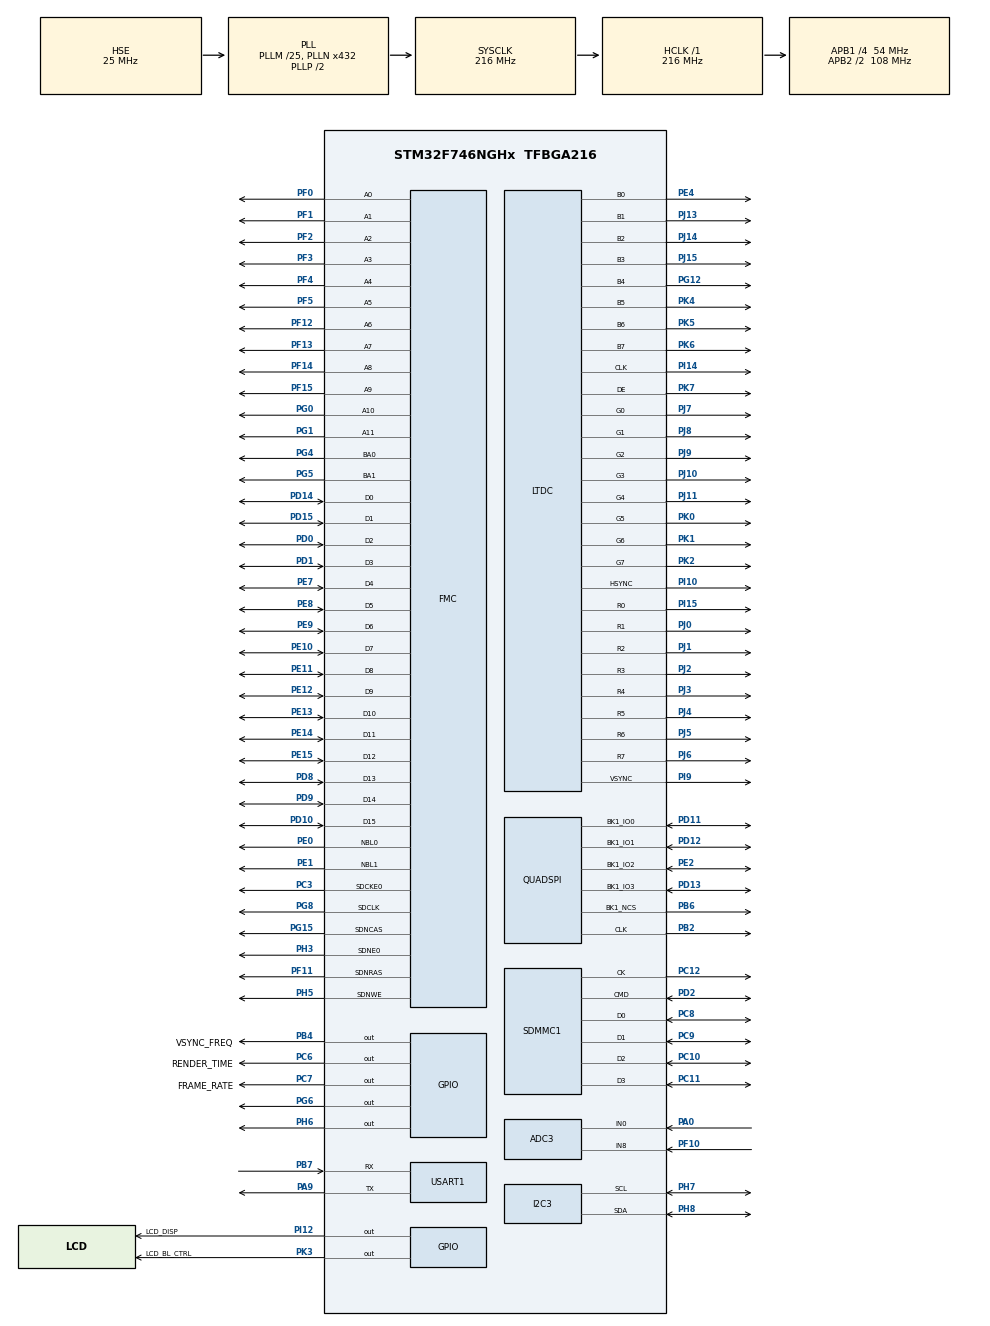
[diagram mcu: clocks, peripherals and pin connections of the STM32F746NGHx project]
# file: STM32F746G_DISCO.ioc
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ADC3.Channel-0\#ChannelRegularConversion=ADC_CHANNEL_0
ADC3.Channel-1\#ChannelRegularConversion=ADC_CHANNEL_8
ADC3.ContinuousConvMode=ENABLE
ADC3.DMAContinuousRequests=ENABLE
ADC3.NbrOfConversion=2
ADC3.NbrOfConversionFlag=1
ADC3.Rank-0\#ChannelRegularConversion=1
ADC3.Rank-1\#ChannelRegularConversion=2
ADC3.SamplingTime-0\#ChannelRegularConversion=ADC_SAMPLETIME_480CYCLES
ADC3.SamplingTime-1\#ChannelRegularConversion=ADC_SAMPLETIME_480CYCLES
ADC3.ScanConvMode=ADC_SCAN_ENABLE
CORTEX_M7.ART_ACCLERATOR_ENABLE=1
CORTEX_M7.AccessPermission-Cortex_Memory_Protection_Unit_Region0_Settings=MPU_REGION_FULL_ACCESS
CORTEX_M7.AccessPermission-Cortex_Memory_Protection_Unit_Region1_Settings=MPU_REGION_FULL_ACCESS
CORTEX_M7.BaseAddress-Cortex_Memory_Protection_Unit_Region0_Settings=0x90000000
CORTEX_M7.BaseAddress-Cortex_Memory_Protection_Unit_Region1_Settings=0x90000000
CORTEX_M7.CPU_DCache=Enabled
CORTEX_M7.CPU_ICache=Enabled
CORTEX_M7.Enable-Cortex_Memory_Protection_Unit_Region0_Settings=MPU_REGION_ENABLE
CORTEX_M7.Enable-Cortex_Memory_Protection_Unit_Region1_Settings=MPU_REGION_ENABLE
CORTEX_M7.IsCacheable-Cortex_Memory_Protection_Unit_Region1_Settings=MPU_ACCESS_CACHEABLE
CORTEX_M7.MPU_Control=MPU_PRIVILEGED_DEFAULT
CORTEX_M7.PREFETCH_ENABLE=1
CORTEX_M7.Size-Cortex_Memory_Protection_Unit_Region0_Settings=MPU_REGION_SIZE_256MB
CORTEX_M7.Size-Cortex_Memory_Protection_Unit_Region1_Settings=MPU_REGION_SIZE_16MB
Dma.ADC3.2.Direction=DMA_PERIPH_TO_MEMORY
Dma.ADC3.2.FIFOMode=DMA_FIFOMODE_DISABLE
Dma.ADC3.2.Instance=DMA2_Stream0
Dma.ADC3.2.MemDataAlignment=DMA_MDATAALIGN_HALFWORD
Dma.ADC3.2.MemInc=DMA_MINC_ENABLE
Dma.ADC3.2.Mode=DMA_CIRCULAR
Dma.ADC3.2.PeriphDataAlignment=DMA_PDATAALIGN_HALFWORD
Dma.ADC3.2.PeriphInc=DMA_PINC_DISABLE
Dma.ADC3.2.Priority=DMA_PRIORITY_LOW
Dma.Request0=SDMMC1_RX
Dma.Request1=SDMMC1_TX
Dma.Request2=ADC3
Dma.SDMMC1_RX.0.Direction=DMA_PERIPH_TO_MEMORY
Dma.SDMMC1_RX.0.FIFOMode=DMA_FIFOMODE_ENABLE
Dma.SDMMC1_RX.0.FIFOThreshold=DMA_FIFO_THRESHOLD_FULL
Dma.SDMMC1_RX.0.Instance=DMA2_Stream3
Dma.SDMMC1_RX.0.MemBurst=DMA_MBURST_INC4
Dma.SDMMC1_RX.0.MemDataAlignment=DMA_MDATAALIGN_WORD
Dma.SDMMC1_RX.0.MemInc=DMA_MINC_ENABLE
Dma.SDMMC1_RX.0.Mode=DMA_PFCTRL
Dma.SDMMC1_RX.0.PeriphBurst=DMA_PBURST_INC4
Dma.SDMMC1_RX.0.PeriphDataAlignment=DMA_PDATAALIGN_WORD
Dma.SDMMC1_RX.0.PeriphInc=DMA_PINC_DISABLE
Dma.SDMMC1_RX.0.Priority=DMA_PRIORITY_LOW
Dma.SDMMC1_TX.1.Direction=DMA_MEMORY_TO_PERIPH
Dma.SDMMC1_TX.1.FIFOMode=DMA_FIFOMODE_ENABLE
Dma.SDMMC1_TX.1.FIFOThreshold=DMA_FIFO_THRESHOLD_FULL
Dma.SDMMC1_TX.1.Instance=DMA2_Stream6
Dma.SDMMC1_TX.1.MemBurst=DMA_MBURST_INC4
Dma.SDMMC1_TX.1.MemDataAlignment=DMA_MDATAALIGN_WORD
Dma.SDMMC1_TX.1.MemInc=DMA_MINC_ENABLE
Dma.SDMMC1_TX.1.Mode=DMA_PFCTRL
Dma.SDMMC1_TX.1.PeriphBurst=DMA_PBURST_INC4
Dma.SDMMC1_TX.1.PeriphDataAlignment=DMA_PDATAALIGN_WORD
Dma.SDMMC1_TX.1.PeriphInc=DMA_PINC_DISABLE
Dma.SDMMC1_TX.1.Priority=DMA_PRIORITY_LOW
FATFS._MAX_SS=4096
FMC.CASLatency1=FMC_SDRAM_CAS_LATENCY_3
FMC.ExitSelfRefreshDelay1=7
FMC.LoadToActiveDelay1=2
FMC.RCDDelay1=2
FMC.RPDelay1=2
FMC.ReadBurst1=FMC_SDRAM_RBURST_ENABLE
FMC.RowCycleDelay1=7
FMC.SDClockPeriod1=FMC_SDRAM_CLOCK_PERIOD_2
FMC.SelfRefreshTime1=4
FMC.WriteRecoveryTime1=3
FREERTOS.Queues01=adcCurrentQueue,10,uint16_t,0,Dynamic,NULL,NULL;adcVoltageQueue,10,uint16_t,0,Dynamic,NULL,NULL;sdQueue,16,uint16_t,0,Dynamic,NULL,NULL
FREERTOS.Tasks01=defaultTask,24,128,StartDefaultTask,Default,NULL,Dynamic,NULL,NULL;TouchGFXTask,24,4096,TouchGFX_Task,As external,NULL,Dynamic,NULL,NULL;videoTask,8,1000,videoTaskFunc,As external,NULL,Dynamic,NULL,NULL;adcCurrentTask,8,128,StartAdcCurrentTask,Default,NULL,Dynamic,NULL,NULL;adcVoltageTask,8,128,StartAdcVoltageTask,Default,NULL,Dynamic,NULL,NULL;sdTask,8,128,StartSDTask,Default,NULL,Dynamic,NULL,NULL
FREERTOS.configTOTAL_HEAP_SIZE=75000
FREERTOS.configUSE_APPLICATION_TASK_TAG=1
FREERTOS.configUSE_IDLE_HOOK=1
I2C3.Timing=0x20404768
LIBJPEG.RGB_ORDERING=BGR
LTDC.ActiveH=272
LTDC.ActiveW=480
LTDC.Alpha_L0=255
LTDC.FBStartAdress_L0=0xC0000000
LTDC.HBP=13
LTDC.HFP=32
LTDC.HSync=41
LTDC.ImageHeight_L0=272
LTDC.ImageWidth_L0=480
LTDC.Layers=0
LTDC.PixelFormat_L0=LTDC_PIXEL_FORMAT_RGB565
LTDC.VSync=10
LTDC.WindowX1_L0=480
LTDC.WindowY1_L0=272
Mcu.Family=STM32F7
Mcu.Name=STM32F746NGHx
Mcu.Package=TFBGA216
NVIC.DMA2D_IRQn=true\:5\:0\:true\:false\:true\:true\:true\:true\:true
NVIC.DMA2_Stream0_IRQn=true\:5\:0\:false\:false\:true\:true\:false\:true\:true
NVIC.DMA2_Stream3_IRQn=true\:5\:0\:false\:false\:true\:true\:false\:true\:true
NVIC.DMA2_Stream6_IRQn=true\:5\:0\:false\:false\:true\:true\:false\:true\:true
NVIC.LTDC_IRQn=true\:5\:0\:true\:false\:true\:true\:true\:true\:true
NVIC.PriorityGroup=NVIC_PRIORITYGROUP_4
NVIC.SDMMC1_IRQn=true\:5\:0\:false\:false\:true\:true\:true\:true\:true
NVIC.TIM6_DAC_IRQn=true\:0\:0\:false\:false\:true\:false\:false\:true\:true
NVIC.TimeBase=TIM6_DAC_IRQn
NVIC.TimeBaseIP=TIM6
PA0/WKUP.Signal=ADCx_IN0
PA13.Mode=Serial_Wire
PA13.Signal=SYS_JTMS-SWDIO
PA14.Mode=Serial_Wire
PA14.Signal=SYS_JTCK-SWCLK
PA9.Mode=Asynchronous
PA9.Signal=USART1_TX
PB2.Mode=Single Bank 1
PB2.Signal=QUADSPI_CLK
PB4.GPIO_Label=VSYNC_FREQ
PB4.GPIO_Speed=GPIO_SPEED_FREQ_VERY_HIGH
PB4.Signal=GPIO_Output
PB6.Mode=Single Bank 1
PB6.Signal=QUADSPI_BK1_NCS
PB7.Mode=Asynchronous
PB7.Signal=USART1_RX
PC10.Mode=SD_4_bits_Wide_bus
PC10.Signal=SDMMC1_D2
PC11.Mode=SD_4_bits_Wide_bus
PC11.Signal=SDMMC1_D3
PC12.Mode=SD_4_bits_Wide_bus
PC12.Signal=SDMMC1_CK
PC14/OSC32_IN.Mode=LSE-External-Oscillator
PC14/OSC32_IN.Signal=RCC_OSC32_IN
PC15/OSC32_OUT.Mode=LSE-External-Oscillator
PC15/OSC32_OUT.Signal=RCC_OSC32_OUT
PC3.Mode=SdramChipSelect1_1
PC3.Signal=FMC_SDCKE0
PC6.GPIO_Label=RENDER_TIME
PC6.GPIO_Speed=GPIO_SPEED_FREQ_VERY_HIGH
PC6.Signal=GPIO_Output
PC7.GPIO_Label=FRAME_RATE
PC7.GPIO_Speed=GPIO_SPEED_FREQ_VERY_HIGH
PC7.Signal=GPIO_Output
PC8.Mode=SD_4_bits_Wide_bus
PC8.Signal=SDMMC1_D0
PC9.Mode=SD_4_bits_Wide_bus
PC9.Signal=SDMMC1_D1
PD0.Signal=FMC_D2_DA2
PD1.Signal=FMC_D3_DA3
PD10.Signal=FMC_D15_DA15
PD11.Mode=Single Bank 1
PD11.Signal=QUADSPI_BK1_IO0
PD12.Mode=Single Bank 1
PD12.Signal=QUADSPI_BK1_IO1
PD13.Mode=Single Bank 1
PD13.Signal=QUADSPI_BK1_IO3
PD14.Signal=FMC_D0_DA0
PD15.Signal=FMC_D1_DA1
PD2.Mode=SD_4_bits_Wide_bus
PD2.Signal=SDMMC1_CMD
PD8.Signal=FMC_D13_DA13
PD9.Signal=FMC_D14_DA14
PE0.Signal=FMC_NBL0
PE1.Signal=FMC_NBL1
PE10.Signal=FMC_D7_DA7
PE11.Signal=FMC_D8_DA8
PE12.Signal=FMC_D9_DA9
PE13.Signal=FMC_D10_DA10
PE14.Signal=FMC_D11_DA11
PE15.Signal=FMC_D12_DA12
PE2.Mode=Single Bank 1
PE2.Signal=QUADSPI_BK1_IO2
PE4.Mode=RGB888
PE4.Signal=LTDC_B0
PE7.Signal=FMC_D4_DA4
PE8.Signal=FMC_D5_DA5
PE9.Signal=FMC_D6_DA6
PF0.Signal=FMC_A0
PF1.Signal=FMC_A1
PF10.Mode=IN8
PF10.Signal=ADC3_IN8
PF11.Signal=FMC_SDNRAS
PF12.Signal=FMC_A6
PF13.Signal=FMC_A7
PF14.Signal=FMC_A8
PF15.Signal=FMC_A9
PF2.Signal=FMC_A2
PF3.Signal=FMC_A3
PF4.Signal=FMC_A4
PF5.Signal=FMC_A5
PG0.Signal=FMC_A10
PG1.Signal=FMC_A11
PG12.Mode=RGB888
PG12.Signal=LTDC_B4
PG15.Signal=FMC_SDNCAS
PG4.Signal=FMC_A14_BA0
PG5.Signal=FMC_A15_BA1
PG6.GPIO_PuPd=GPIO_PULLDOWN
PG6.PinState=GPIO_PIN_SET
PG6.Signal=GPIO_Output
PG8.Signal=FMC_SDCLK
PH0/OSC_IN.Mode=HSE-External-Oscillator
PH0/OSC_IN.Signal=RCC_OSC_IN
PH1/OSC_OUT.Mode=HSE-External-Oscillator
PH1/OSC_OUT.Signal=RCC_OSC_OUT
PH3.Mode=SdramChipSelect1_1
PH3.Signal=FMC_SDNE0
PH5.Signal=FMC_SDNWE
PH6.GPIO_PuPd=GPIO_PULLDOWN
PH6.PinState=GPIO_PIN_SET
PH6.Signal=GPIO_Output
PH7.GPIO_Pu=GPIO_PULLUP
PH7.Mode=I2C
PH7.Signal=I2C3_SCL
PH8.GPIO_Pu=GPIO_PULLUP
PH8.Mode=I2C
PH8.Signal=I2C3_SDA
PI10.Mode=RGB888
PI10.Signal=LTDC_HSYNC
PI12.GPIO_Label=LCD_DISP
PI12.PinState=GPIO_PIN_SET
PI12.Signal=GPIO_Output
PI14.Mode=RGB888
PI14.Signal=LTDC_CLK
PI15.Mode=RGB888
PI15.Signal=LTDC_R0
PI9.Mode=RGB888
PI9.Signal=LTDC_VSYNC
PJ0.Mode=RGB888
PJ0.Signal=LTDC_R1
PJ1.Mode=RGB888
PJ1.Signal=LTDC_R2
PJ10.Mode=RGB888
PJ10.Signal=LTDC_G3
PJ11.Mode=RGB888
PJ11.Signal=LTDC_G4
PJ13.Mode=RGB888
PJ13.Signal=LTDC_B1
PJ14.Mode=RGB888
PJ14.Signal=LTDC_B2
PJ15.Mode=RGB888
PJ15.Signal=LTDC_B3
PJ2.Mode=RGB888
PJ2.Signal=LTDC_R3
PJ3.Mode=RGB888
PJ3.Signal=LTDC_R4
PJ4.Mode=RGB888
PJ4.Signal=LTDC_R5
PJ5.Mode=RGB888
PJ5.Signal=LTDC_R6
PJ6.Mode=RGB888
PJ6.Signal=LTDC_R7
PJ7.Mode=RGB888
PJ7.Signal=LTDC_G0
PJ8.Mode=RGB888
PJ8.Signal=LTDC_G1
PJ9.Mode=RGB888
PJ9.Signal=LTDC_G2
PK0.Mode=RGB888
PK0.Signal=LTDC_G5
PK1.Mode=RGB888
PK1.Signal=LTDC_G6
PK2.Mode=RGB888
PK2.Signal=LTDC_G7
PK3.GPIO_Label=LCD_BL_CTRL
PK3.PinState=GPIO_PIN_SET
PK3.Signal=GPIO_Output
PK4.Mode=RGB888
PK4.Signal=LTDC_B5
PK5.Mode=RGB888
PK5.Signal=LTDC_B6
PK6.Mode=RGB888
PK6.Signal=LTDC_B7
PK7.Mode=RGB888
PK7.Signal=LTDC_DE
ProjectManager.HeapSize=0xA00
ProjectManager.StackSize=0xA00
ProjectManager.TargetToolchain=STM32CubeIDE
QUADSPI.ChipSelectHighTime=QSPI_CS_HIGH_TIME_6_CYCLE
QUADSPI.ClockPrescaler=1
QUADSPI.FifoThreshold=4
QUADSPI.FlashSize=24
QUADSPI.SampleShifting=QSPI_SAMPLE_SHIFTING_HALFCYCLE
RCC.AHBFreq_Value=216000000
RCC.APB1CLKDivider=RCC_HCLK_DIV4
RCC.APB1Freq_Value=54000000
RCC.APB1TimFreq_Value=108000000
RCC.APB2CLKDivider=RCC_HCLK_DIV2
RCC.APB2Freq_Value=108000000
RCC.APB2TimFreq_Value=216000000
RCC.CortexFreq_Value=216000000
RCC.HCLKFreq_Value=216000000
RCC.HSE_VALUE=25000000
RCC.HSI_VALUE=16000000
RCC.PLLI2SN=100
RCC.PLLM=25
RCC.PLLN=432
RCC.PLLQ=9
RCC.PLLSAIR=3
RCC.PLLSourceVirtual=RCC_PLLSOURCE_HSE
RCC.RTCClockSelection=RCC_RTCCLKSOURCE_LSE
RCC.SDMMCClockSelection=RCC_SDMMC1CLKSOURCE_CLK48
RCC.SYSCLKFreq_VALUE=216000000
RCC.SYSCLKSource=RCC_SYSCLKSOURCE_PLLCLK
RCC.USBFreq_Value=48000000
RCC.VCOOutputFreq_Value=432000000
RTC.Date=23
RTC.Format=RTC_FORMAT_BIN
RTC.Hours=23
RTC.Minutes=59
RTC.Month=RTC_MONTH_MARCH
RTC.Seconds=45
RTC.WakeUpClock-WakeUp=RTC_WAKEUPCLOCK_CK_SPRE_16BITS
RTC.WakeUpCounter-WakeUp=4
RTC.WeekDay=RTC_WEEKDAY_SATURDAY
RTC.Year=24
SH.ADCx_IN0.0=ADC3_IN0,IN0
SH.FMC_A0.0=FMC_A0,12b-sda1
SH.FMC_A1.0=FMC_A1,12b-sda1
SH.FMC_A10.0=FMC_A10,12b-sda1
SH.FMC_A11.0=FMC_A11,12b-sda1
SH.FMC_A14_BA0.0=FMC_BA0,FourSdramBanks1
SH.FMC_A15_BA1.0=FMC_BA1,FourSdramBanks1
SH.FMC_A2.0=FMC_A2,12b-sda1
SH.FMC_A3.0=FMC_A3,12b-sda1
SH.FMC_A4.0=FMC_A4,12b-sda1
SH.FMC_A5.0=FMC_A5,12b-sda1
SH.FMC_A6.0=FMC_A6,12b-sda1
SH.FMC_A7.0=FMC_A7,12b-sda1
SH.FMC_A8.0=FMC_A8,12b-sda1
SH.FMC_A9.0=FMC_A9,12b-sda1
SH.FMC_D0_DA0.0=FMC_D0,sd-16b-d1
SH.FMC_D10_DA10.0=FMC_D10,sd-16b-d1
SH.FMC_D11_DA11.0=FMC_D11,sd-16b-d1
SH.FMC_D12_DA12.0=FMC_D12,sd-16b-d1
SH.FMC_D13_DA13.0=FMC_D13,sd-16b-d1
SH.FMC_D14_DA14.0=FMC_D14,sd-16b-d1
SH.FMC_D15_DA15.0=FMC_D15,sd-16b-d1
SH.FMC_D1_DA1.0=FMC_D1,sd-16b-d1
SH.FMC_D2_DA2.0=FMC_D2,sd-16b-d1
SH.FMC_D3_DA3.0=FMC_D3,sd-16b-d1
SH.FMC_D4_DA4.0=FMC_D4,sd-16b-d1
SH.FMC_D5_DA5.0=FMC_D5,sd-16b-d1
SH.FMC_D6_DA6.0=FMC_D6,sd-16b-d1
SH.FMC_D7_DA7.0=FMC_D7,sd-16b-d1
SH.FMC_D8_DA8.0=FMC_D8,sd-16b-d1
SH.FMC_D9_DA9.0=FMC_D9,sd-16b-d1
SH.FMC_NBL0.0=FMC_NBL0,Sd2ByteEnable1
SH.FMC_NBL1.0=FMC_NBL1,Sd2ByteEnable1
SH.FMC_SDCLK.0=FMC_SDCLK,12b-sda1
SH.FMC_SDNCAS.0=FMC_SDNCAS,12b-sda1
SH.FMC_SDNRAS.0=FMC_SDNRAS,12b-sda1
SH.FMC_SDNWE.0=FMC_SDNWE,12b-sda1
STMicroelectronics.X-CUBE-TOUCHGFX.4.23.1.ApplicationCcGraphicsJjApplication=TouchGFXOoGenerator
STMicroelectronics.X-CUBE-TOUCHGFX.4.23.1.tgfx_address1=0xC0000000
STMicroelectronics.X-CUBE-TOUCHGFX.4.23.1.tgfx_address2=0xC003FC00
STMicroelectronics.X-CUBE-TOUCHGFX.4.23.1.tgfx_buffering_strategy=Double
STMicroelectronics.X-CUBE-TOUCHGFX.4.23.1.tgfx_display_interface=disp_ltdc
STMicroelectronics.X-CUBE-TOUCHGFX.4.23.1.tgfx_hardware_accelerator=dma_2d
STMicroelectronics.X-CUBE-TOUCHGFX.4.23.1.tgfx_location=Allocate
STMicroelectronics.X-CUBE-TOUCHGFX.4.23.1.tgfx_vector_fonts=Enabled
STMicroelectronics.X-CUBE-TOUCHGFX.4.23.1.tgfx_vector_rendering=Software
STMicroelectronics.X-CUBE-TOUCHGFX.4.23.1.tgfx_video=Software
STMicroelectronics.X-CUBE-TOUCHGFX.4.23.1.tgfx_video_buffer_format=RGB565\:2
STMicroelectronics.X-CUBE-TOUCHGFX.4.23.1.tgfx_video_height=272
STMicroelectronics.X-CUBE-TOUCHGFX.4.23.1.tgfx_video_strategy=2
STMicroelectronics.X-CUBE-TOUCHGFX.4.23.1.tgfx_video_width=480
STMicroelectronics.X-CUBE-TOUCHGFX.4.23.1.tgfx_vsync=vsync_ltdc
USART1.VirtualMode-Asynchronous=VM_ASYNC
VP_CRC_VS_CRC.Mode=CRC_Activate
VP_DMA2D_VS_DMA2D.Mode=DMA2D_Activate
VP_FATFS_VS_SDIO.Mode=SDIO
VP_FREERTOS_VS_CMSIS_V2.Mode=CMSIS_V2
VP_LIBJPEG_VS_JPEGLIB.Mode=Enabled
VP_RTC_VS_RTC_Activate.Mode=RTC_Enabled
VP_RTC_VS_RTC_Calendar.Mode=RTC_Calendar
VP_RTC_VS_RTC_WakeUp_intern.Mode=WakeUp
VP_STMicroelectronics.X-CUBE-TOUCHGFX_VS_GraphicsJjApplication_4.23.1.Mode=GraphicsJjApplication
VP_SYS_VS_tim6.Mode=TIM6
board=custom

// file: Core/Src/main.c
/* USER CODE BEGIN Header */
/**
  ******************************************************************************
  * @file           : main.c
  * @brief          : Main program body
  ******************************************************************************
  * @attention
  *
  * <h2><center>&copy; Copyright (c) 2020 STMicroelectronics.
  * All rights reserved.</center></h2>
  *
  * This software component is licensed by ST under Ultimate Liberty license
  * SLA0044, the "License"; You may not use this file except in compliance with
  * the License. You may obtain a copy of the License at:
  *                             www.st.com/SLA0044
  *
  ******************************************************************************
  */
/* USER CODE END Header */
#include "main.h"
#include "cmsis_os.h"
#include "fatfs.h"
#include "libjpeg.h"
#include "app_touchgfx.h"

/* USER CODE BEGIN Includes */
#include <stm32746g_discovery_qspi.h>
#include <stm32746g_discovery.h>
#include <stdio.h>
#include <string.h>

/* USER CODE END Includes */

/* USER CODE BEGIN PD */

#define REFRESH_COUNT        1835

#define SDRAM_TIMEOUT                            ((uint32_t)0xFFFF)
#define SDRAM_MODEREG_BURST_LENGTH_1             ((uint16_t)0x0000)
#define SDRAM_MODEREG_BURST_LENGTH_2             ((uint16_t)0x0001)
#define SDRAM_MODEREG_BURST_LENGTH_4             ((uint16_t)0x0002)
#define SDRAM_MODEREG_BURST_LENGTH_8             ((uint16_t)0x0004)
#define SDRAM_MODEREG_BURST_TYPE_SEQUENTIAL      ((uint16_t)0x0000)
#define SDRAM_MODEREG_BURST_TYPE_INTERLEAVED     ((uint16_t)0x0008)
#define SDRAM_MODEREG_CAS_LATENCY_2              ((uint16_t)0x0020)
#define SDRAM_MODEREG_CAS_LATENCY_3              ((uint16_t)0x0030)
#define SDRAM_MODEREG_OPERATING_MODE_STANDARD    ((uint16_t)0x0000)
#define SDRAM_MODEREG_WRITEBURST_MODE_PROGRAMMED ((uint16_t)0x0000)
#define SDRAM_MODEREG_WRITEBURST_MODE_SINGLE     ((uint16_t)0x0200)

/* USER CODE END PD */

ADC_HandleTypeDef hadc3;
DMA_HandleTypeDef hdma_adc3;

CRC_HandleTypeDef hcrc;

DMA2D_HandleTypeDef hdma2d;

I2C_HandleTypeDef hi2c3;

LTDC_HandleTypeDef hltdc;

QSPI_HandleTypeDef hqspi;

RTC_HandleTypeDef hrtc;

SD_HandleTypeDef hsd1;
DMA_HandleTypeDef hdma_sdmmc1_rx;
DMA_HandleTypeDef hdma_sdmmc1_tx;

UART_HandleTypeDef huart1;

SDRAM_HandleTypeDef hsdram1;

/* Definitions for defaultTask */
//osThreadId_t defaultTaskHandle;
//const osThreadAttr_t defaultTask_attributes = {
//  .name = "defaultTask",
//  .stack_size = 128 * 4,
//  .priority = (osPriority_t) osPriorityNormal,
//};
/* Definitions for TouchGFXTask */
osThreadId_t TouchGFXTaskHandle;
const osThreadAttr_t TouchGFXTask_attributes = {
  .name = "TouchGFXTask",
  .stack_size = 4096 * 4,
  .priority = (osPriority_t) osPriorityNormal,
};
/* Definitions for videoTask */
osThreadId_t videoTaskHandle;
const osThreadAttr_t videoTask_attributes = {
  .name = "videoTask",
  .stack_size = 1000 * 4,
  .priority = (osPriority_t) osPriorityLow,
};
/* Definitions for adcCurrentTask */
osThreadId_t adcCurrentTaskHandle;
const osThreadAttr_t adcCurrentTask_attributes = {
  .name = "adcCurrentTask",
  .stack_size = 128 * 4,
  .priority = (osPriority_t) osPriorityLow,
};
/* Definitions for adcVoltageTask */
osThreadId_t adcVoltageTaskHandle;
const osThreadAttr_t adcVoltageTask_attributes = {
  .name = "adcVoltageTask",
  .stack_size = 128 * 4,
  .priority = (osPriority_t) osPriorityLow,
};
/* Definitions for sdTask */
osThreadId_t sdTaskHandle;
const osThreadAttr_t sdTask_attributes = {
  .name = "sdTask",
  .stack_size = 128 * 4,
  .priority = (osPriority_t) osPriorityLow,
};
/* Definitions for adcCurrentQueue */
osMessageQueueId_t adcCurrentQueueHandle;
const osMessageQueueAttr_t adcCurrentQueue_attributes = {
  .name = "adcCurrentQueue"
};
/* Definitions for adcVoltageQueue */
osMessageQueueId_t adcVoltageQueueHandle;
const osMessageQueueAttr_t adcVoltageQueue_attributes = {
  .name = "adcVoltageQueue"
};
/* Definitions for sdQueue */
osMessageQueueId_t sdQueueHandle;
const osMessageQueueAttr_t sdQueue_attributes = {
  .name = "sdQueue"
};
/* USER CODE BEGIN PV */

osThreadId_t secondTaskHandle;
const osThreadAttr_t secondTask_attributes = {
  .name = "secondTask",
  .stack_size = 1000 * 4,
  .priority = (osPriority_t) osPriorityLow,
};

#ifdef __GNUC__
  #define PUTCHAR_PROTOTYPE int __io_putchar(int ch)
#else
  #define PUTCHAR_PROTOTYPE int fputc(int ch, FILE *f)
#endif

RTC_TimeTypeDef RTC_Time;
RTC_DateTypeDef RTC_Date;
RTC_TimeTypeDef sTime;

static FMC_SDRAM_CommandTypeDef Command;
/* USER CODE END PV */

void SystemClock_Config(void);
static void MPU_Config(void);
static void MX_GPIO_Init(void);
static void MX_DMA_Init(void);
static void MX_DMA2D_Init(void);
static void MX_FMC_Init(void);
static void MX_I2C3_Init(void);
static void MX_LTDC_Init(void);
static void MX_QUADSPI_Init(void);
static void MX_ADC3_Init(void);
static void MX_USART1_UART_Init(void);
static void MX_RTC_Init(void);
static void MX_SDMMC1_SD_Init(void);
static void MX_CRC_Init(void);
//void StartDefaultTask(void *argument);
extern void TouchGFX_Task(void *argument);
extern void videoTaskFunc(void *argument);
void StartAdcCurrentTask(void *argument);
void StartAdcVoltageTask(void *argument);
void StartSDTask(void *argument);

/* USER CODE BEGIN PFP */
void secondTask(void *argument);

#define DMA_BUFFER_SIZE 2
uint32_t dma_buffer[DMA_BUFFER_SIZE];

PUTCHAR_PROTOTYPE
{
	HAL_UART_Transmit(&huart1, (uint8_t *)&ch, 1, 0xFFFF);
	return ch;
}

/* USER CODE END PFP */

/* USER CODE BEGIN 0 */

uint16_t ADC_val_current = 0;
uint16_t ADC_val_voltage = 0;

int map(int x, int in_min, int in_max, int out_min, int out_max)
{
  return (x - in_min) * (out_max - out_min + 1) / (in_max - in_min + 1) + out_min;
}

//SD Card variables FATFS
//uint8_t retSD;    /* Return value for SD */
//char SDPath[4];   /* SD logical drive path */
//FATFS SDFatFS;    /* File system object for SD logical drive */
//FIL SDFile;       /* File object for SD */
float mAh;

//FILE I/O variables
FRESULT res;									/* FastFs function common result code */
uint32_t byteswritten, bytesread;				/* File write/read counts */
uint8_t wtext[]= "testtext";  			        /* File write buffer */
uint8_t rtext[100];								/* File read buffer */

/* USER CODE END 0 */

int main(void)
{

  /* MPU Configuration--------------------------------------------------------*/
  MPU_Config();
/* Enable the CPU Cache */

  /* Enable I-Cache---------------------------------------------------------*/
  SCB_EnableICache();

  /* Enable D-Cache---------------------------------------------------------*/
  SCB_EnableDCache();

  /* MCU Configuration--------------------------------------------------------*/

  /* Reset of all peripherals, Initializes the Flash interface and the Systick. */
  HAL_Init();

  /* Configure the system clock */
  SystemClock_Config();

  /* Initialize all configured peripherals */
  MX_GPIO_Init();
  MX_DMA_Init();
  MX_DMA2D_Init();
  MX_FMC_Init();
  MX_I2C3_Init();
  MX_LTDC_Init();
  MX_QUADSPI_Init();
  MX_LIBJPEG_Init();
  MX_ADC3_Init();
  MX_USART1_UART_Init();
  MX_RTC_Init();
  MX_SDMMC1_SD_Init();
  MX_CRC_Init();
  MX_FATFS_Init();
  MX_TouchGFX_Init();
  /* Call PreOsInit function */
  MX_TouchGFX_PreOSInit();
  /* USER CODE BEGIN 2 */

//  float call_C_calcMilliAh(C *p);
//
//  void ccc(struct C* p)
//  {
//	  float mAh = call_C_calcMilliAh(p);
//	  printf("mAh %f\n", mAh);
//  }

  // Use mAh as needed

  // Redirect the standard output to UART
//  int _write(int file, char *ptr, int len) {
//      int DataIdx;
//      for (DataIdx = 0; DataIdx < len; DataIdx++) {
//          __io_putchar(*ptr++);
//      }
//      return len;
//  }

  /* USER CODE END 2 */

  /* Init scheduler */
  osKernelInitialize();

  /* Create the queue(s) */
  /* creation of adcCurrentQueue */
  adcCurrentQueueHandle = osMessageQueueNew (10, sizeof(uint16_t), &adcCurrentQueue_attributes);

  /* creation of adcVoltageQueue */
  adcVoltageQueueHandle = osMessageQueueNew (10, sizeof(uint16_t), &adcVoltageQueue_attributes);

  /* creation of sdQueue */
  sdQueueHandle = osMessageQueueNew (16, sizeof(uint32_t), &sdQueue_attributes);

  /* Create the thread(s) */
  /* creation of defaultTask */
//  defaultTaskHandle = osThreadNew(StartDefaultTask, NULL, &defaultTask_attributes);

  /* creation of TouchGFXTask */
  TouchGFXTaskHandle = osThreadNew(TouchGFX_Task, NULL, &TouchGFXTask_attributes);

  /* creation of videoTask */
  videoTaskHandle = osThreadNew(videoTaskFunc, NULL, &videoTask_attributes);

  /* creation of adcCurrentTask */
  adcCurrentTaskHandle = osThreadNew(StartAdcCurrentTask, NULL, &adcCurrentTask_attributes);

  /* creation of adcVoltageTask */
  adcVoltageTaskHandle = osThreadNew(StartAdcVoltageTask, NULL, &adcVoltageTask_attributes);

  /* creation of sdTask */
  sdTaskHandle = osThreadNew(StartSDTask, NULL, &sdTask_attributes);

  /* USER CODE BEGIN RTOS_THREADS */

  //secondTaskHandle = osThreadNew(secondTask, NULL, &secondTask_attributes);

  /* add threads, ... */
  /* USER CODE END RTOS_THREADS */

  /* Start scheduler */
  osKernelStart();

  /* We should never get here as control is now taken by the scheduler */
  /* Infinite loop */
  while (1)
  {

  }
}

void SystemClock_Config(void)
{
  RCC_OscInitTypeDef RCC_OscInitStruct = {0};
  RCC_ClkInitTypeDef RCC_ClkInitStruct = {0};

  /** Configure LSE Drive Capability
  */
  HAL_PWR_EnableBkUpAccess();
  __HAL_RCC_LSEDRIVE_CONFIG(RCC_LSEDRIVE_LOW);

  /** Configure the main internal regulator output voltage
  */
  __HAL_RCC_PWR_CLK_ENABLE();
  __HAL_PWR_VOLTAGESCALING_CONFIG(PWR_REGULATOR_VOLTAGE_SCALE1);

  /** Initializes the RCC Oscillators according to the specified parameters
  * in the RCC_OscInitTypeDef structure.
  */
  RCC_OscInitStruct.OscillatorType = RCC_OSCILLATORTYPE_HSE|RCC_OSCILLATORTYPE_LSE;
  RCC_OscInitStruct.HSEState = RCC_HSE_ON;
  RCC_OscInitStruct.LSEState = RCC_LSE_ON;
  RCC_OscInitStruct.PLL.PLLState = RCC_PLL_ON;
  RCC_OscInitStruct.PLL.PLLSource = RCC_PLLSOURCE_HSE;
  RCC_OscInitStruct.PLL.PLLM = 25;
  RCC_OscInitStruct.PLL.PLLN = 432;
  RCC_OscInitStruct.PLL.PLLP = RCC_PLLP_DIV2;
  RCC_OscInitStruct.PLL.PLLQ = 9;
  if (HAL_RCC_OscConfig(&RCC_OscInitStruct) != HAL_OK)
  {
    Error_Handler();
  }

  /** Activate the Over-Drive mode
  */
  if (HAL_PWREx_EnableOverDrive() != HAL_OK)
  {
    Error_Handler();
  }

  /** Initializes the CPU, AHB and APB buses clocks
  */
  RCC_ClkInitStruct.ClockType = RCC_CLOCKTYPE_HCLK|RCC_CLOCKTYPE_SYSCLK
                              |RCC_CLOCKTYPE_PCLK1|RCC_CLOCKTYPE_PCLK2;
  RCC_ClkInitStruct.SYSCLKSource = RCC_SYSCLKSOURCE_PLLCLK;
  RCC_ClkInitStruct.AHBCLKDivider = RCC_SYSCLK_DIV1;
  RCC_ClkInitStruct.APB1CLKDivider = RCC_HCLK_DIV4;
  RCC_ClkInitStruct.APB2CLKDivider = RCC_HCLK_DIV2;

  if (HAL_RCC_ClockConfig(&RCC_ClkInitStruct, FLASH_LATENCY_7) != HAL_OK)
  {
    Error_Handler();
  }
}

static void MX_ADC3_Init(void)
{

  ADC_ChannelConfTypeDef sConfig = {0};

  /** Configure the global features of the ADC (Clock, Resolution, Data Alignment and number of conversion)
  */
  hadc3.Instance = ADC3;
  hadc3.Init.ClockPrescaler = ADC_CLOCK_SYNC_PCLK_DIV4;
  hadc3.Init.Resolution = ADC_RESOLUTION_12B;
  hadc3.Init.ScanConvMode = ADC_SCAN_ENABLE;
  hadc3.Init.ContinuousConvMode = ENABLE;
  hadc3.Init.DiscontinuousConvMode = DISABLE;
  hadc3.Init.ExternalTrigConvEdge = ADC_EXTERNALTRIGCONVEDGE_NONE;
  hadc3.Init.ExternalTrigConv = ADC_SOFTWARE_START;
  hadc3.Init.DataAlign = ADC_DATAALIGN_RIGHT;
  hadc3.Init.NbrOfConversion = 2;
  hadc3.Init.DMAContinuousRequests = ENABLE;
  hadc3.Init.EOCSelection = ADC_EOC_SINGLE_CONV;
  if (HAL_ADC_Init(&hadc3) != HAL_OK)
  {
    Error_Handler();
  }

  /** Configure for the selected ADC regular channel its corresponding rank in the sequencer and its sample time.
  */
  sConfig.Channel = ADC_CHANNEL_0;
  sConfig.Rank = ADC_REGULAR_RANK_1;
  sConfig.SamplingTime = ADC_SAMPLETIME_480CYCLES;
  if (HAL_ADC_ConfigChannel(&hadc3, &sConfig) != HAL_OK)
  {
    Error_Handler();
  }

  /** Configure for the selected ADC regular channel its corresponding rank in the sequencer and its sample time.
  */
  sConfig.Channel = ADC_CHANNEL_8;
  sConfig.Rank = ADC_REGULAR_RANK_2;
  if (HAL_ADC_ConfigChannel(&hadc3, &sConfig) != HAL_OK)
  {
    Error_Handler();
  }

}

static void MX_CRC_Init(void)
{

  hcrc.Instance = CRC;
  hcrc.Init.DefaultPolynomialUse = DEFAULT_POLYNOMIAL_ENABLE;
  hcrc.Init.DefaultInitValueUse = DEFAULT_INIT_VALUE_ENABLE;
  hcrc.Init.InputDataInversionMode = CRC_INPUTDATA_INVERSION_NONE;
  hcrc.Init.OutputDataInversionMode = CRC_OUTPUTDATA_INVERSION_DISABLE;
  hcrc.InputDataFormat = CRC_INPUTDATA_FORMAT_BYTES;
  if (HAL_CRC_Init(&hcrc) != HAL_OK)
  {
    Error_Handler();
  }

}

static void MX_DMA2D_Init(void)
{

  hdma2d.Instance = DMA2D;
  hdma2d.Init.Mode = DMA2D_M2M;
  hdma2d.Init.ColorMode = DMA2D_OUTPUT_ARGB8888;
  hdma2d.Init.OutputOffset = 0;
  hdma2d.LayerCfg[1].InputOffset = 0;
  hdma2d.LayerCfg[1].InputColorMode = DMA2D_INPUT_ARGB8888;
  hdma2d.LayerCfg[1].AlphaMode = DMA2D_NO_MODIF_ALPHA;
  hdma2d.LayerCfg[1].InputAlpha = 0;
  if (HAL_DMA2D_Init(&hdma2d) != HAL_OK)
  {
    Error_Handler();
  }
  if (HAL_DMA2D_ConfigLayer(&hdma2d, 1) != HAL_OK)
  {
    Error_Handler();
  }

}

static void MX_I2C3_Init(void)
{

  /* USER CODE BEGIN I2C3_Init 0 */
  HAL_Delay(100); //Delay to fix initialization issue on some boards
  /* USER CODE END I2C3_Init 0 */

  hi2c3.Instance = I2C3;
  hi2c3.Init.Timing = 0x20404768;
  hi2c3.Init.OwnAddress1 = 0;
  hi2c3.Init.AddressingMode = I2C_ADDRESSINGMODE_7BIT;
  hi2c3.Init.DualAddressMode = I2C_DUALADDRESS_DISABLE;
  hi2c3.Init.OwnAddress2 = 0;
  hi2c3.Init.OwnAddress2Masks = I2C_OA2_NOMASK;
  hi2c3.Init.GeneralCallMode = I2C_GENERALCALL_DISABLE;
  hi2c3.Init.NoStretchMode = I2C_NOSTRETCH_DISABLE;
  if (HAL_I2C_Init(&hi2c3) != HAL_OK)
  {
    Error_Handler();
  }

  /** Configure Analogue filter
  */
  if (HAL_I2CEx_ConfigAnalogFilter(&hi2c3, I2C_ANALOGFILTER_ENABLE) != HAL_OK)
  {
    Error_Handler();
  }

  /** Configure Digital filter
  */
  if (HAL_I2CEx_ConfigDigitalFilter(&hi2c3, 0) != HAL_OK)
  {
    Error_Handler();
  }

}

static void MX_LTDC_Init(void)
{

  LTDC_LayerCfgTypeDef pLayerCfg = {0};

  hltdc.Instance = LTDC;
  hltdc.Init.HSPolarity = LTDC_HSPOLARITY_AL;
  hltdc.Init.VSPolarity = LTDC_VSPOLARITY_AL;
  hltdc.Init.DEPolarity = LTDC_DEPOLARITY_AL;
  hltdc.Init.PCPolarity = LTDC_PCPOLARITY_IPC;
  hltdc.Init.HorizontalSync = 40;
  hltdc.Init.VerticalSync = 9;
  hltdc.Init.AccumulatedHBP = 53;
  hltdc.Init.AccumulatedVBP = 11;
  hltdc.Init.AccumulatedActiveW = 533;
  hltdc.Init.AccumulatedActiveH = 283;
  hltdc.Init.TotalWidth = 565;
  hltdc.Init.TotalHeigh = 285;
  hltdc.Init.Backcolor.Blue = 0;
  hltdc.Init.Backcolor.Green = 0;
  hltdc.Init.Backcolor.Red = 0;
  if (HAL_LTDC_Init(&hltdc) != HAL_OK)
  {
    Error_Handler();
  }
  pLayerCfg.WindowX0 = 0;
  pLayerCfg.WindowX1 = 480;
  pLayerCfg.WindowY0 = 0;
  pLayerCfg.WindowY1 = 272;
  pLayerCfg.PixelFormat = LTDC_PIXEL_FORMAT_RGB565;
  pLayerCfg.Alpha = 255;
  pLayerCfg.Alpha0 = 0;
  pLayerCfg.BlendingFactor1 = LTDC_BLENDING_FACTOR1_CA;
  pLayerCfg.BlendingFactor2 = LTDC_BLENDING_FACTOR2_CA;
  pLayerCfg.FBStartAdress = 0xC0000000;
  pLayerCfg.ImageWidth = 480;
  pLayerCfg.ImageHeight = 272;
  pLayerCfg.Backcolor.Blue = 0;
  pLayerCfg.Backcolor.Green = 0;
  pLayerCfg.Backcolor.Red = 0;
  if (HAL_LTDC_ConfigLayer(&hltdc, &pLayerCfg, 0) != HAL_OK)
  {
    Error_Handler();
  }

}

static void MX_QUADSPI_Init(void)
{

  /* QUADSPI parameter configuration*/
  hqspi.Instance = QUADSPI;
  hqspi.Init.ClockPrescaler = 1;
  hqspi.Init.FifoThreshold = 4;
  hqspi.Init.SampleShifting = QSPI_SAMPLE_SHIFTING_HALFCYCLE;
  hqspi.Init.FlashSize = 24;
  hqspi.Init.ChipSelectHighTime = QSPI_CS_HIGH_TIME_6_CYCLE;
  hqspi.Init.ClockMode = QSPI_CLOCK_MODE_0;
  hqspi.Init.FlashID = QSPI_FLASH_ID_1;
  hqspi.Init.DualFlash = QSPI_DUALFLASH_DISABLE;
  if (HAL_QSPI_Init(&hqspi) != HAL_OK)
  {
    Error_Handler();
  }
  /* USER CODE BEGIN QUADSPI_Init 2 */
  BSP_QSPI_Init();

  BSP_QSPI_MemoryMappedMode();
  HAL_NVIC_DisableIRQ(QUADSPI_IRQn);
  /* USER CODE END QUADSPI_Init 2 */

}

static void MX_RTC_Init(void)
{

  RTC_TimeTypeDef sTime = {0};
  RTC_DateTypeDef sDate = {0};

  /** Initialize RTC Only
  */
  hrtc.Instance = RTC;
  hrtc.Init.HourFormat = RTC_HOURFORMAT_24;
  hrtc.Init.AsynchPrediv = 127;
  hrtc.Init.SynchPrediv = 255;
  hrtc.Init.OutPut = RTC_OUTPUT_DISABLE;
  hrtc.Init.OutPutPolarity = RTC_OUTPUT_POLARITY_HIGH;
  hrtc.Init.OutPutType = RTC_OUTPUT_TYPE_OPENDRAIN;
  if (HAL_RTC_Init(&hrtc) != HAL_OK)
  {
    Error_Handler();
  }

  /** Initialize RTC and set the Time and Date
  */
  sTime.Hours = 23;
  sTime.Minutes = 59;
  sTime.Seconds = 1;
  sTime.DayLightSaving = RTC_DAYLIGHTSAVING_NONE;
  sTime.StoreOperation = RTC_STOREOPERATION_RESET;
  if (HAL_RTC_SetTime(&hrtc, &sTime, RTC_FORMAT_BIN) != HAL_OK)
  {
    Error_Handler();
  }
  sDate.WeekDay = RTC_WEEKDAY_SATURDAY;
  sDate.Month = RTC_MONTH_MARCH;
  sDate.Date = 23;
  sDate.Year = 24;

  if (HAL_RTC_SetDate(&hrtc, &sDate, RTC_FORMAT_BIN) != HAL_OK)
  {
    Error_Handler();
  }

  /** Enable the WakeUp
  */
  if (HAL_RTCEx_SetWakeUpTimer(&hrtc, 4, RTC_WAKEUPCLOCK_CK_SPRE_16BITS) != HAL_OK)
  {
    Error_Handler();
  }

}

static void MX_SDMMC1_SD_Init(void)
{

  hsd1.Instance = SDMMC1;
  hsd1.Init.ClockEdge = SDMMC_CLOCK_EDGE_RISING;
  hsd1.Init.ClockBypass = SDMMC_CLOCK_BYPASS_DISABLE;
  hsd1.Init.ClockPowerSave = SDMMC_CLOCK_POWER_SAVE_DISABLE;
  hsd1.Init.BusWide = SDMMC_BUS_WIDE_4B;
  hsd1.Init.HardwareFlowControl = SDMMC_HARDWARE_FLOW_CONTROL_DISABLE;
  hsd1.Init.ClockDiv = 0;

}

static void MX_USART1_UART_Init(void)
{

  huart1.Instance = USART1;
  huart1.Init.BaudRate = 115200;
  huart1.Init.WordLength = UART_WORDLENGTH_8B;
  huart1.Init.StopBits = UART_STOPBITS_1;
  huart1.Init.Parity = UART_PARITY_NONE;
  huart1.Init.Mode = UART_MODE_TX_RX;
  huart1.Init.HwFlowCtl = UART_HWCONTROL_NONE;
  huart1.Init.OverSampling = UART_OVERSAMPLING_16;
  huart1.Init.OneBitSampling = UART_ONE_BIT_SAMPLE_DISABLE;
  huart1.AdvancedInit.AdvFeatureInit = UART_ADVFEATURE_NO_INIT;
  if (HAL_UART_Init(&huart1) != HAL_OK)
  {
    Error_Handler();
  }

}

static void MX_DMA_Init(void)
{

  /* DMA controller clock enable */
  __HAL_RCC_DMA2_CLK_ENABLE();

  /* DMA interrupt init */
  /* DMA2_Stream0_IRQn interrupt configuration */
  HAL_NVIC_SetPriority(DMA2_Stream0_IRQn, 5, 0);
  HAL_NVIC_EnableIRQ(DMA2_Stream0_IRQn);
  /* DMA2_Stream3_IRQn interrupt configuration */
  HAL_NVIC_SetPriority(DMA2_Stream3_IRQn, 5, 0);
  HAL_NVIC_EnableIRQ(DMA2_Stream3_IRQn);
  /* DMA2_Stream6_IRQn interrupt configuration */
  HAL_NVIC_SetPriority(DMA2_Stream6_IRQn, 5, 0);
  HAL_NVIC_EnableIRQ(DMA2_Stream6_IRQn);

}

/* FMC initialization function */
static void MX_FMC_Init(void)
{

  FMC_SDRAM_TimingTypeDef SdramTiming = {0};

  /** Perform the SDRAM1 memory initialization sequence
  */
  hsdram1.Instance = FMC_SDRAM_DEVICE;
  /* hsdram1.Init */
  hsdram1.Init.SDBank = FMC_SDRAM_BANK1;
  hsdram1.Init.ColumnBitsNumber = FMC_SDRAM_COLUMN_BITS_NUM_8;
  hsdram1.Init.RowBitsNumber = FMC_SDRAM_ROW_BITS_NUM_12;
  hsdram1.Init.MemoryDataWidth = FMC_SDRAM_MEM_BUS_WIDTH_16;
  hsdram1.Init.InternalBankNumber = FMC_SDRAM_INTERN_BANKS_NUM_4;
  hsdram1.Init.CASLatency = FMC_SDRAM_CAS_LATENCY_3;
  hsdram1.Init.WriteProtection = FMC_SDRAM_WRITE_PROTECTION_DISABLE;
  hsdram1.Init.SDClockPeriod = FMC_SDRAM_CLOCK_PERIOD_2;
  hsdram1.Init.ReadBurst = FMC_SDRAM_RBURST_ENABLE;
  hsdram1.Init.ReadPipeDelay = FMC_SDRAM_RPIPE_DELAY_0;
  /* SdramTiming */
  SdramTiming.LoadToActiveDelay = 2;
  SdramTiming.ExitSelfRefreshDelay = 7;
  SdramTiming.SelfRefreshTime = 4;
  SdramTiming.RowCycleDelay = 7;
  SdramTiming.WriteRecoveryTime = 3;
  SdramTiming.RPDelay = 2;
  SdramTiming.RCDDelay = 2;

  if (HAL_SDRAM_Init(&hsdram1, &SdramTiming) != HAL_OK)
  {
    Error_Handler( );
  }

  /* USER CODE BEGIN FMC_Init 2 */
  __IO uint32_t tmpmrd = 0;

    /* Step 1: Configure a clock configuration enable command */
    Command.CommandMode            = FMC_SDRAM_CMD_CLK_ENABLE;
    Command.CommandTarget          =  FMC_SDRAM_CMD_TARGET_BANK1;
    Command.AutoRefreshNumber      = 1;
    Command.ModeRegisterDefinition = 0;

    /* Send the command */
    HAL_SDRAM_SendCommand(&hsdram1, &Command, SDRAM_TIMEOUT);

    /* Step 2: Insert 100 us minimum delay */
    /* Inserted delay is equal to 1 ms due to systick time base unit (ms) */
    HAL_Delay(1);

    /* Step 3: Configure a PALL (precharge all) command */
    Command.CommandMode            = FMC_SDRAM_CMD_PALL;
    Command.CommandTarget          = FMC_SDRAM_CMD_TARGET_BANK1;
    Command.AutoRefreshNumber      = 1;
    Command.ModeRegisterDefinition = 0;

    /* Send the command */
    HAL_SDRAM_SendCommand(&hsdram1, &Command, SDRAM_TIMEOUT);

    /* Step 4: Configure an Auto Refresh command */
    Command.CommandMode            = FMC_SDRAM_CMD_AUTOREFRESH_MODE;
    Command.CommandTarget          = FMC_SDRAM_CMD_TARGET_BANK1;
    Command.AutoRefreshNumber      = 8;
    Command.ModeRegisterDefinition = 0;

    /* Send the command */
    HAL_SDRAM_SendCommand(&hsdram1, &Command, SDRAM_TIMEOUT);

    /* Step 5: Program the external memory mode register */
    tmpmrd = (uint32_t)SDRAM_MODEREG_BURST_LENGTH_1 | \
             SDRAM_MODEREG_BURST_TYPE_SEQUENTIAL    | \
             SDRAM_MODEREG_CAS_LATENCY_3            | \
             SDRAM_MODEREG_OPERATING_MODE_STANDARD  | \
             SDRAM_MODEREG_WRITEBURST_MODE_SINGLE;

    Command.CommandMode            = FMC_SDRAM_CMD_LOAD_MODE;
    Command.CommandTarget          = FMC_SDRAM_CMD_TARGET_BANK1;
    Command.AutoRefreshNumber      = 1;
    Command.ModeRegisterDefinition = tmpmrd;

    /* Send the command */
    HAL_SDRAM_SendCommand(&hsdram1, &Command, SDRAM_TIMEOUT);

    /* Step 6: Set the refresh rate counter */
    /* Set the device refresh rate */
    HAL_SDRAM_ProgramRefreshRate(&hsdram1, REFRESH_COUNT);

    //Deactivate speculative/cache access to first FMC Bank to save FMC bandwidth
    FMC_Bank1->BTCR[0] = 0x000030D2;
  /* USER CODE END FMC_Init 2 */
}

static void MX_GPIO_Init(void)
{
  GPIO_InitTypeDef GPIO_InitStruct = {0};

  /* GPIO Ports Clock Enable */
  __HAL_RCC_GPIOE_CLK_ENABLE();
  __HAL_RCC_GPIOB_CLK_ENABLE();
  __HAL_RCC_GPIOC_CLK_ENABLE();
  __HAL_RCC_GPIOA_CLK_ENABLE();
  __HAL_RCC_GPIOG_CLK_ENABLE();
  __HAL_RCC_GPIOJ_CLK_ENABLE();
  __HAL_RCC_GPIOD_CLK_ENABLE();
  __HAL_RCC_GPIOK_CLK_ENABLE();
  __HAL_RCC_GPIOF_CLK_ENABLE();
  __HAL_RCC_GPIOI_CLK_ENABLE();
  __HAL_RCC_GPIOH_CLK_ENABLE();

  /*Configure GPIO pin Output Level */
  HAL_GPIO_WritePin(VSYNC_FREQ_GPIO_Port, VSYNC_FREQ_Pin, GPIO_PIN_RESET);

  /*Configure GPIO pin Output Level */
  HAL_GPIO_WritePin(LCD_BL_CTRL_GPIO_Port, LCD_BL_CTRL_Pin, GPIO_PIN_SET);

  /*Configure GPIO pin Output Level */
  HAL_GPIO_WritePin(LCD_DISP_GPIO_Port, LCD_DISP_Pin, GPIO_PIN_SET);

  /*Configure GPIO pin Output Level */
  HAL_GPIO_WritePin(GPIOC, FRAME_RATE_Pin|RENDER_TIME_Pin, GPIO_PIN_RESET);

  /*Configure GPIO pin Output Level */
  HAL_GPIO_WritePin(GPIOG, GPIO_PIN_6, GPIO_PIN_SET);

  /*Configure GPIO pin Output Level */
  HAL_GPIO_WritePin(GPIOH, GPIO_PIN_6, GPIO_PIN_SET);

  /*Configure GPIO pin : VSYNC_FREQ_Pin */
  GPIO_InitStruct.Pin = VSYNC_FREQ_Pin;
  GPIO_InitStruct.Mode = GPIO_MODE_OUTPUT_PP;
  GPIO_InitStruct.Pull = GPIO_NOPULL;
  GPIO_InitStruct.Speed = GPIO_SPEED_FREQ_VERY_HIGH;
  HAL_GPIO_Init(VSYNC_FREQ_GPIO_Port, &GPIO_InitStruct);

  /*Configure GPIO pin : LCD_BL_CTRL_Pin */
  GPIO_InitStruct.Pin = LCD_BL_CTRL_Pin;
  GPIO_InitStruct.Mode = GPIO_MODE_OUTPUT_PP;
  GPIO_InitStruct.Pull = GPIO_NOPULL;
  GPIO_InitStruct.Speed = GPIO_SPEED_FREQ_LOW;
  HAL_GPIO_Init(LCD_BL_CTRL_GPIO_Port, &GPIO_InitStruct);

  /*Configure GPIO pin : LCD_DISP_Pin */
  GPIO_InitStruct.Pin = LCD_DISP_Pin;
  GPIO_InitStruct.Mode = GPIO_MODE_OUTPUT_PP;
  GPIO_InitStruct.Pull = GPIO_NOPULL;
  GPIO_InitStruct.Speed = GPIO_SPEED_FREQ_LOW;
  HAL_GPIO_Init(LCD_DISP_GPIO_Port, &GPIO_InitStruct);

  /*Configure GPIO pins : FRAME_RATE_Pin RENDER_TIME_Pin */
  GPIO_InitStruct.Pin = FRAME_RATE_Pin|RENDER_TIME_Pin;
  GPIO_InitStruct.Mode = GPIO_MODE_OUTPUT_PP;
  GPIO_InitStruct.Pull = GPIO_NOPULL;
  GPIO_InitStruct.Speed = GPIO_SPEED_FREQ_VERY_HIGH;
  HAL_GPIO_Init(GPIOC, &GPIO_InitStruct);

  /*Configure GPIO pin : PG6 */
  GPIO_InitStruct.Pin = GPIO_PIN_6;
  GPIO_InitStruct.Mode = GPIO_MODE_OUTPUT_PP;
  GPIO_InitStruct.Pull = GPIO_PULLDOWN;
  GPIO_InitStruct.Speed = GPIO_SPEED_FREQ_LOW;
  HAL_GPIO_Init(GPIOG, &GPIO_InitStruct);

  /*Configure GPIO pin : PH6 */
  GPIO_InitStruct.Pin = GPIO_PIN_6;
  GPIO_InitStruct.Mode = GPIO_MODE_OUTPUT_PP;
  GPIO_InitStruct.Pull = GPIO_PULLDOWN;
  GPIO_InitStruct.Speed = GPIO_SPEED_FREQ_LOW;
  HAL_GPIO_Init(GPIOH, &GPIO_InitStruct);

}

/* USER CODE BEGIN 4 */

//extern xQueueHandle messageQ;
unsigned int val = 0;

//void StartDefaultTask(void * argument)
//{
//
//  /* Infinite loop */
//  for(;;)
//  {
//	  xQueueGenericSend(messageQ, &val, 0, xCopyPosition);
//	  val++;
//
//    osDelay(1);
//  }
//  /* USER CODE END 5 */
//}

/* USER CODE END 4 */

//void StartDefaultTask(void *argument)
//{
//  /* USER CODE BEGIN 5 */
//
//
//  /* Infinite loop */
//  for(;;)
//  {
//    osDelay(1);
//  }
//  /* USER CODE END 5 */
//}

void StartAdcCurrentTask(void *argument)
{
  /* USER CODE BEGIN StartAdcCurrentTask */
	ADC_ChannelConfTypeDef sConfig = {0};

  /* Infinite loop */
	  for(;;)
	  {
	    sConfig.Channel = ADC_CHANNEL_8;
	    sConfig.Rank = ADC_REGULAR_RANK_1;
	    sConfig.SamplingTime = ADC_SAMPLETIME_112CYCLES;
	    if (HAL_ADC_ConfigChannel(&hadc3, &sConfig) != HAL_OK)
	    {
	        Error_Handler();
	    }

		HAL_ADC_Start(&hadc3);
		HAL_ADC_PollForConversion(&hadc3, 10);
		int ADC_val_current = HAL_ADC_GetValue(&hadc3);
		HAL_ADC_Stop(&hadc3);
		printf("adc inside main.c CurrentTask %d\n", ADC_val_current);

		osMessageQueuePut(adcCurrentQueueHandle, &ADC_val_current, 0, 0);

		osDelay(10);
	  }
  /* USER CODE END StartAdcCurrentTask */
}

void StartAdcVoltageTask(void *argument)
{
  /* USER CODE BEGIN StartAdcVoltageTask */
	ADC_ChannelConfTypeDef sConfig = {0};

  /* Infinite loop */
    for(;;)
    {
        sConfig.Channel = ADC_CHANNEL_0;
        sConfig.Rank = ADC_REGULAR_RANK_1;
        sConfig.SamplingTime = ADC_SAMPLETIME_112CYCLES;
        if (HAL_ADC_ConfigChannel(&hadc3, &sConfig) != HAL_OK)
        {
            Error_Handler();
        }

        HAL_ADC_Start(&hadc3);
        HAL_ADC_PollForConversion(&hadc3, 10);
        int ADC_val_voltage = HAL_ADC_GetValue(&hadc3);
        HAL_ADC_Stop(&hadc3);

        osMessageQueuePut(adcVoltageQueueHandle, &ADC_val_voltage, 0, 0);

        osDelay(1000);
    }
  /* USER CODE END StartAdcVoltageTask */
}

void StartSDTask(void *argument)
{
  /* USER CODE BEGIN StartSDTask */

	    for (;;) {
	    	printf("Hello SDTask \n"); // Debug print
	    	SD_Operation_t operation;
	    	FATFS SDFatFS;
	        FIL SDFile;
	        FRESULT res;
	    	UINT byteswritten, bytesread;
	    	f_mount(&SDFatFS, (TCHAR const*)SDPath, 0);
	    	//	    char wtext[20]; // Buffer to hold the formatted mAh value
	    	//	    char rtext[20]; // Buffer to read from the SD card

	    		    // Mount the SD card
	        printf("loop \n"); // Debug print
	        if (osMessageQueueGet(sdQueueHandle, &operation, 0, osWaitForever) == osOK) {
	        	printf("Received SD operation: %d\n", operation.command); // Debug print
	            switch (operation.command) {
	                case SD_WRITE:
	                    // Open file for writing
	                    if (f_open(&SDFile, "F7FILE1.TXT", FA_CREATE_ALWAYS | FA_WRITE) == FR_OK) {
	                        // Write data to text file
	                        res = f_write(&SDFile, operation.data, strlen(operation.data), &byteswritten);
	                        if (res != FR_OK || byteswritten == 0) {
	                            printf("Failed to write file!\r\n");
	                        } else {
	                            printf("File written successfully\r\n");
	                            printf("Write Content: %s\r\n", operation.data);
	                        }
	                        f_close(&SDFile);
	                    } else {
	                        printf("Failed to open Write file\r\n");
	                    }
	                    break;
	                case SD_READ:
	                    // Open file for reading
	                    if (f_open(&SDFile, "F7FILE1.TXT", FA_READ) == FR_OK) {
	                        memset(rtext, 0, sizeof(rtext));
	                        res = f_read(&SDFile, rtext, sizeof(rtext), &bytesread);
	                        if (res != FR_OK || bytesread == 0) {
	                            printf("Failed to read file!\r\n");
	                        } else {
	                            printf("File read successfully\r\n");
	                            printf("File content: %s\r\n", rtext);
	                        }
	                        f_close(&SDFile);
	                    } else {
	                        printf("Failed to open Read file\r\n");
	                    }
	                    break;
	                default:
	                	printf("Nothing to do");
	            }
	        }
	    }
	}
  /* USER CODE END StartSDTask */

/* MPU Configuration */

void MPU_Config(void)
{
  MPU_Region_InitTypeDef MPU_InitStruct = {0};

  /* Disables the MPU */
  HAL_MPU_Disable();

  /** Initializes and configures the Region and the memory to be protected
  */
  MPU_InitStruct.Enable = MPU_REGION_ENABLE;
  MPU_InitStruct.Number = MPU_REGION_NUMBER0;
  MPU_InitStruct.BaseAddress = 0x90000000;
  MPU_InitStruct.Size = MPU_REGION_SIZE_256MB;
  MPU_InitStruct.SubRegionDisable = 0x0;
  MPU_InitStruct.TypeExtField = MPU_TEX_LEVEL0;
  MPU_InitStruct.AccessPermission = MPU_REGION_FULL_ACCESS;
  MPU_InitStruct.DisableExec = MPU_INSTRUCTION_ACCESS_ENABLE;
  MPU_InitStruct.IsShareable = MPU_ACCESS_NOT_SHAREABLE;
  MPU_InitStruct.IsCacheable = MPU_ACCESS_NOT_CACHEABLE;
  MPU_InitStruct.IsBufferable = MPU_ACCESS_NOT_BUFFERABLE;

  HAL_MPU_ConfigRegion(&MPU_InitStruct);

  /** Initializes and configures the Region and the memory to be protected
  */
  MPU_InitStruct.Number = MPU_REGION_NUMBER1;
  MPU_InitStruct.Size = MPU_REGION_SIZE_16MB;
  MPU_InitStruct.IsCacheable = MPU_ACCESS_CACHEABLE;

  HAL_MPU_ConfigRegion(&MPU_InitStruct);
  /* Enables the MPU */
  HAL_MPU_Enable(MPU_PRIVILEGED_DEFAULT);

}

void HAL_TIM_PeriodElapsedCallback(TIM_HandleTypeDef *htim)
{
  if (htim->Instance == TIM6) {
    HAL_IncTick();
  }
}

void Error_Handler(void)
{
}
